# RN821X_RN721X_SOC_V2 register map
File version: v1.0.7
CPU: CM0 r0p0, little endian, no MPU, no FPU, 3 interrupt priority bits
Registers are 32-bit, read-write, reset 0x0 unless marked. A register's access mark holds for its fields unless they carry their own. Offsets are from the block's base; [hi:lo] are bit positions; {n}, {i} and the like mark numbered series; 'fields as' and 'values as' point back to an identical list.

## LPUART — Flicker calculation module
Base 0x40070000
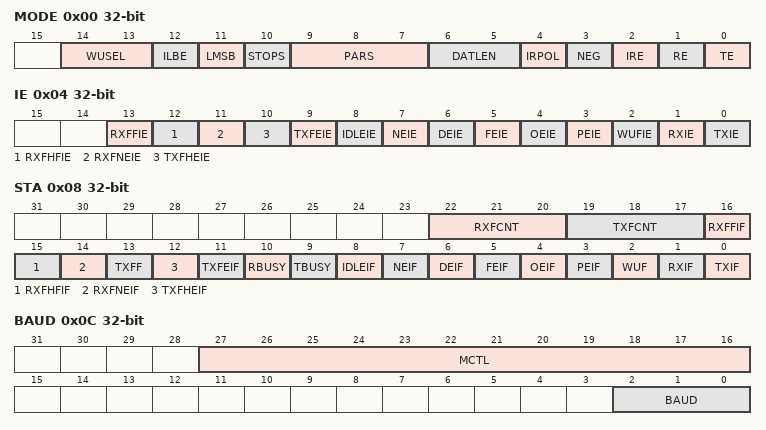
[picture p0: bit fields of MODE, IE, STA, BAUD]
0x00 MODE reset not defined — LPUART mode configuration register
  [14:13] WUSEL — wake up interrupt event selection bits
    0=START (select as start bit wake up); 1=RX (select as RX negedge wake up); 2=RX_DONE (select as data receive done wake up); 3=MATCH (select as one frame data match wake up)
  [12] ILBE — inner loopback enable bit
    0=DIS (inner loopback disable); 1=EN (inner loopback enable)
  [11] LMSB — LSB/MSB transfer mode selection bit
    0=L (LSB first transfer mode); 1=M (MSB first transfer mode)
  [10] STOPS — stop bit width selection bit
    0=1BIT (stop bit_width select as 1 bit); 1=2BIT (stop bit_width select as 2 bit)
  [9:7] PARS — parity type selection bits
    0=NUL (parity type select as no parity); 1=ODD (parity type select as odd parity); 2=EVEN (parity type select as even parity); 3=parity type select as stick_zero parity; 4=parity type select as stick one parity; 5=USER (parity type select as user_defined parity)
  [6:5] DATLEN — transfer bit-width selection bits(do not include parity bit)
    {v}=data length select as {v+5} bits (v=0..3)
  [4] IRPOL — infra-red modulation polarity selection
    0=P (positive polarity (default driving voltage is high)); 1=N (negative polarity (default driving voltage is low))
  [3] NEG — transfer polarity selection bit
    values as IRPOL
  [2] IRE — infra-red modulation enable bit
    0=DIS (infra-red modulation disable); 1=EN (infra-red modulation enable)
  [1] RE — LPUART receive enable bit
    0=DIS (LPUART receive disable); 1=EN (LPUART receive enable)
  [0] TE — LPUART transmit enable bit
    0=DIS (LPUART transmit disable); 1=EN (LPUART transmit enable)
0x04 IE reset not defined — LPUART interrupt enable register
  [13] RXFFIE — Receive FIFO full interrupt flag enable bit
  [12] RXFHFIE — Receive FIFO half-full interrupt flag enable bit
  [11] RXFNEIE — Receive FIFO empty interrupt flag enable bit
  [10] TXFHEIE — Transmit FIFO half-empty interrupt flag enable bit
  [9] TXFEIE — Transmit FIFO empty interrupt flag enabled bit
  [8] IDLEIE — IDLE frame detection interrupt enable bit
  [7] NEIE — Noise detection of start bit enable bit
  [6] DEIE — Data error interrupt enable bit
  [5] FEIE — Frame format error interrupt enable bit
  [4] OEIE — Overflow error interrupt enable bit
  [3] PEIE — Parity error interrupt enable bit
  [2] WUFIE — Wake-up interrupt enable bit (Wake-up from hibernation mode)
  [1] RXIE — Receive data complete interrupt enable bit
  [0] TXIE — Transmit data complete interrupt enable bit
0x08 STA (reset mask 0x800) — LPUART status indicator register
  [22:20] RXFCNT write-1-clears — Receive FIFO data number bits
  [19:17] TXFCNT write-1-clears — Transmit FIFO data number bits
  [16] RXFFIF write-1-clears — Receive FIFO full interrupt flag
  [15] RXFHFIF write-1-clears — Receive FIFO half-full interrupt flag
  [14] RXFNEIF write-1-clears — Receive FIFO empty interrupt flag
  [13] TXFF write-1-clears — Transmit FIFO full Mark (one to clear or hardware automatically clear)
  [12] TXFHEIF write-1-clears — A transmit FIFO half-empty interrupt flag
  [11] TXFEIF write-1-clears — Transmit FIFO empty interrupt
  [10] RBUSY ro — Receive status flag
  [9] TBUSY ro — Transmit status flag
  [8] IDLEIF write-1-clears — Idle frames detect interrupt flag
  [7] NEIF write-1-clears — Start bit noise detection flag
  [6] DEIF write-1-clears — Data error flag
  [5] FEIF write-1-clears — Frame format error flag
  [4] OEIF write-1-clears — Overflow error flag
  [3] PEIF write-1-clears — Parity error flag
  [2] WUF write-1-clears — Receive wake-up event flag
  [1] RXIF ro — Receive complete interrupt flag
  [0] TXIF ro — Transmit complete interrupt flag
0x0C BAUD reset not defined — LPUART baud rate modulation register
  [27:16] MCTL — LPUART bit-width modulation configuration bits
    0x4A5=9600REC (9600 baud recommend modulation value); 0xF7F=4800REC (4800 baud recommend modulation value); 0x6DB=2400REC (2400 baud recommend modulation value); 0x249=1200REC (1200 baud recommend modulation value); 0xB6D=600REC (600 baud recommend modulation value); 0x111=300REC (300 baud recommend modulation value)
  [2:0] BAUD — LPUART baud rate selection bits
    0=9600BPS (LPUART baudrate select as 9600 bps); 1=4800BPS (LPUART baudrate select as 4800 bps); 2=2400BPS (LPUART baudrate select as 2400 bps); 3=1200BPS (LPUART baudrate select as 1200 bps); 4=600BPS (LPUART baudrate select as 600 bps); 5=300BPS (LPUART baudrate select as 300 bps)
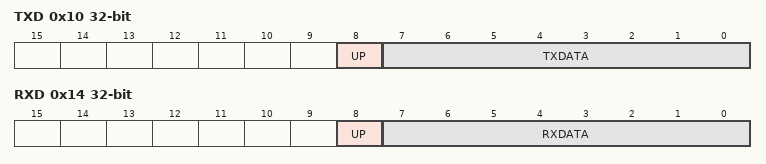
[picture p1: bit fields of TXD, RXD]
0x10 TXD reset not defined — LPUART sends data buffer register
  [8] UP — user-defined parity bit(valid when user-defined parity selected)
  [7:0] TXDATA — transmit data value bits
0x14 RXD ro reset not defined — LPUART receives data buffer register
  [8] UP — user-defined parity bit(valid when user-defined parity selected)
  [7:0] RXDATA — read data value
0x18 DMR 8-bit reset not defined — LPUART data matching register
  [7:0] DMR — LPUART data matches register bits
